VERSION "HIPBNYYYYYYYYYYYYYYYYYYYYYYYYYYYYYYYYYYYYY/4/%%%/4/'%**4YYY///"

NS_ :

BS_:

BU_: Controller Motor Sensor

BO_ 100 ControllerMsg: 4 Controller
 SG_ MOTOR_CMD_angular_momentum : 0|32@1- (1,0) [0|0] ""  Motor
 SG_ SENSOR_CMD_on_off : 32|1@1+ (1,0) [0|0] ""  Motor

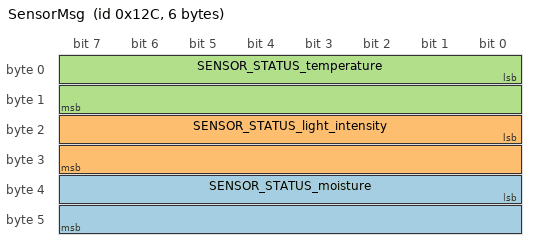
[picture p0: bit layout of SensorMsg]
BO_ 300 SensorMsg: 6 Sensor
 SG_ SENSOR_STATUS_moisture : 32|16@1+ (1,0) [0|0] ""  Controller
 SG_ SENSOR_STATUS_light_intensity : 16|16@1+ (1,0) [0|0] "" Vector__XXX
 SG_ SENSOR_STATUS_temperature : 0|16@1+ (1,0) [0|0] "" Vector__XXX

BO_ 200 MotorMsg: 8 Motor
 SG_ MOTOR_STATUS_angle : 0|32@1- (1,0) [0|0] ""  Controller
 SG_ MOTOR_STATUS_angular_vel : 32|32@1- (1,0) [0|0] ""  Controller

BA_DEF_ SG_  "SensorAttr" INT 0 65535;
BA_DEF_DEF_  "SensorAttr" 91;
BA_ "SensorAttr" SG_ 300 SENSOR_STATUS_moisture 301.1;
BA_ "SensorAttr" SG_ 300 SENSOR_STATUS_light_intensity 302;
BA_ "SensorAttr" SG_ 300 SENSOR_STATUS_temperature 303;
SIG_VALTYPE_ 100 MOTOR_CMD_angular_momentum : 1;
SIG_VALTYPE_ 200 MOTOR_STATUS_angle : 1;
SIG_VALTYPE_ 200 MOTOR_STATUS_angular_vel : 1;
